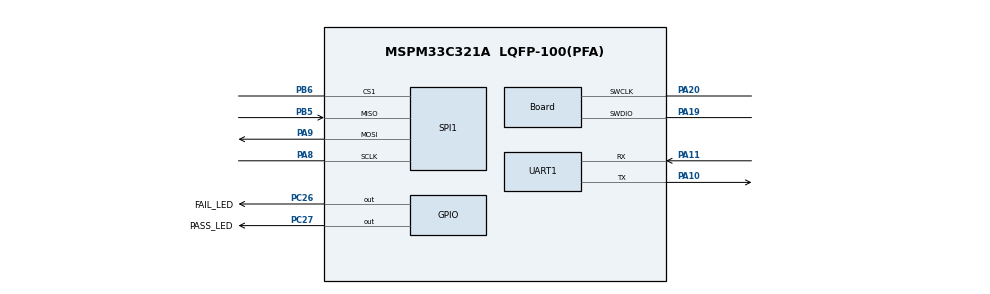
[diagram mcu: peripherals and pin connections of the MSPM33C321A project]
//@cliArgs --device "MSPM33C321A" --package "LQFP-100(PFA)" --part "Default"
//@v2CliArgs --device "MSPM33C321A" --package "LQFP-100(PFA)"
// @cliArgs --board /ti/boards/LP_MSPM33C321A --rtos nortos

/**
 * Import the modules used in this configuration.
 */
const DMA    = scripting.addModule("/ti/driverlib/DMA", {}, false);
const DMA1   = DMA.addInstance();
const GPIO   = scripting.addModule("/ti/driverlib/GPIO", {}, false);
const GPIO1  = GPIO.addInstance();
const SPI    = scripting.addModule("/ti/driverlib/SPI", {}, false);
const SPI1   = SPI.addInstance();
const SYSCTL = scripting.addModule("/ti/driverlib/SYSCTL");
const UART   = scripting.addModule("/ti/driverlib/UART", {}, false);
const UART1  = UART.addInstance();

/**
 * Write custom configuration values to the imported modules.
 */
DMA1.$name = "DMA0";

const Board                       = scripting.addModule("/ti/driverlib/Board", {}, false);
Board.peripheral.$assign          = "DEBUGSS";
Board.peripheral.swclkPin.$assign = "PA20";
Board.peripheral.swdioPin.$assign = "PA19";

GPIO1.$name                                 = "GPIO_LEDS";
GPIO1.associatedPins.create(2);
GPIO1.associatedPins[0].$name               = "FAIL_LED";
GPIO1.associatedPins[0].assignedPort        = "PORTC";
GPIO1.associatedPins[0].assignedPortSegment = "Upper";
GPIO1.associatedPins[0].assignedPin         = "26";
GPIO1.associatedPins[0].launchPadShortcut   = "LED2RedEn";
GPIO1.associatedPins[0].pin.$assign         = "PC26";
GPIO1.associatedPins[1].$name               = "PASS_LED";
GPIO1.associatedPins[1].launchPadShortcut   = "LED2GreenEn";
GPIO1.associatedPins[1].pin.$assign         = "PC27";

SPI1.$name                                 = "SPI_0";
SPI1.rxFifoThreshold                       = "DL_SPI_RX_FIFO_LEVEL_ONE_FRAME";
SPI1.txFifoThreshold                       = "DL_SPI_TX_FIFO_LEVEL_EMPTY";
SPI1.enabledDMAEvent1Triggers              = "DL_SPI_DMA_INTERRUPT_RX";
SPI1.enabledDMAEvent2Triggers              = "DL_SPI_DMA_INTERRUPT_TX";
SPI1.chipSelect                            = ["1"];
SPI1.enabledInterrupts                     = ["DMA_DONE_RX","DMA_DONE_TX"];
SPI1.targetBitRate                         = 25000000;
SPI1.sclkPinConfig.$name                   = "ti_driverlib_gpio_GPIOPinGeneric0";
SPI1.sclkPinConfig.enableConfig            = true;
SPI1.mosiPinConfig.$name                   = "ti_driverlib_gpio_GPIOPinGeneric1";
SPI1.mosiPinConfig.enableConfig            = true;
SPI1.misoPinConfig.$name                   = "ti_driverlib_gpio_GPIOPinGeneric2";
SPI1.misoPinConfig.enableConfig            = true;
SPI1.DMA_CHANNEL_EVENT1.$name              = "CH0";
SPI1.DMA_CHANNEL_EVENT1.addressMode        = "b2b";
SPI1.DMA_CHANNEL_EVENT1.srcLength          = "BYTE";
SPI1.DMA_CHANNEL_EVENT1.dstLength          = "BYTE";
SPI1.DMA_CHANNEL_EVENT1.srcIncDec          = "UNCHANGED";
SPI1.DMA_CHANNEL_EVENT1.peripheral.$assign = "DMA0_CH0";
SPI1.DMA_CHANNEL_EVENT2.$name              = "CH1";
SPI1.DMA_CHANNEL_EVENT2.srcLength          = "BYTE";
SPI1.DMA_CHANNEL_EVENT2.dstLength          = "BYTE";
SPI1.DMA_CHANNEL_EVENT2.addressMode        = "b2b";
SPI1.DMA_CHANNEL_EVENT2.dstIncDec          = "UNCHANGED";
SPI1.DMA_CHANNEL_EVENT2.peripheral.$assign = "DMA0_CH1";
SPI1.peripheral.$assign                    = "UC2";
SPI1.peripheral.sclkPin.$assign            = "PA8";
SPI1.peripheral.mosiPin.$assign            = "PA9";
SPI1.peripheral.misoPin.$assign            = "PB5";
SPI1.peripheral.cs1Pin.$assign             = "PB6";
SPI1.cs1PinConfig.$name                    = "ti_driverlib_gpio_GPIOPinGeneric4";

SYSCTL.forceDefaultClkConfig = true;
SYSCTL.MCLKSource            = "HSCLK";
SYSCTL.SYSPLL_CLK0En         = true;
SYSCTL.SYSPLL_CLK1En         = true;
SYSCTL.SYSPLL_CLK2XEn        = true;
SYSCTL.SYSPLL_Pdiv           = 4;
SYSCTL.SYSPLL_Qdiv           = 25;
SYSCTL.peripheral.$assign    = "SYSCTL";

UART1.$name                    = "UART_0";
UART1.targetBaudRate           = 115200;
UART1.enableFIFO               = true;
UART1.rxFifoThreshold          = "DL_UART_RX_FIFO_LEVEL_ONE_ENTRY";
UART1.txFifoThreshold          = "DL_UART_TX_FIFO_LEVEL_EMPTY";
UART1.peripheral.$assign       = "UC12";
UART1.peripheral.rxPin.$assign = "PA11";
UART1.peripheral.txPin.$assign = "PA10";
UART1.txPinConfig.$name        = "ti_driverlib_gpio_GPIOPinGeneric3";
UART1.rxPinConfig.$name        = "ti_driverlib_gpio_GPIOPinGeneric5";

const ProjectConfig              = scripting.addModule("/ti/project_config/ProjectConfig", {}, false);
ProjectConfig.migrationCondition = true;

ProjectConfig.genLinker  = true;
ProjectConfig.genStartup = true;
ProjectConfig.genOpts    = true;
ProjectConfig.genLibs    = true;
